# WBZ351 register map
Vendor: Microchip
Registers are 32-bit, read-write, reset 0x0 unless marked. A register's access mark holds for its fields unless they carry their own. Addresses are absolute, and some are shared; only a register's first bit layout is shown; [hi:lo] are bit positions; {n}, {i} and the like mark numbered series.

## DSU
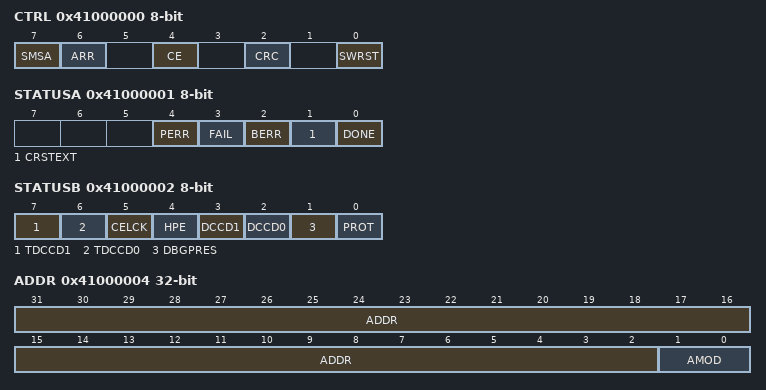
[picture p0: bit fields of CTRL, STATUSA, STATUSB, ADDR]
0x41000000 CTRL 8-bit wo
  [7] SMSA — Start Memory Stream Access
  [6] ARR — Auxiliary Row Read
  [4] CE — Chip-Erase
  [2] CRC — 32-bit Cyclic Redundancy Code
  [0] SWRST — Software Reset
0x41000001 STATUSA 8-bit
  [4] PERR — Protection Error
  [3] FAIL — Failure
  [2] BERR — Bus Error
  [1] CRSTEXT — CPU Reset Phase Extension
  [0] DONE
0x41000002 STATUSB 8-bit ro
  [7] TDCCD1 — Test Debug Communication Channel 1 Dirty
  [6] TDCCD0 — Test Debug Communication Channel 0 Dirty
  [5] CELCK — Chip Erase Locked
  [4] HPE — Hot-Plugging Enable
  [3] DCCD1 — Debug Communication Channel 1 Dirty
  [2] DCCD0 — Debug Communication Channel 0 Dirty
  [1] DBGPRES — Debugger Present
  [0] PROT — Protected
0x41000004 ADDR
  [31:2] ADDR — Address
  [1:0] AMOD — Access Mode
0x41000008 LENGTH
  [31:2] LENGTH
0x4100000C DATA
0x41000010 DCC0
  [31:0] DATA
0x41000014 DCC1
  [31:0] DATA
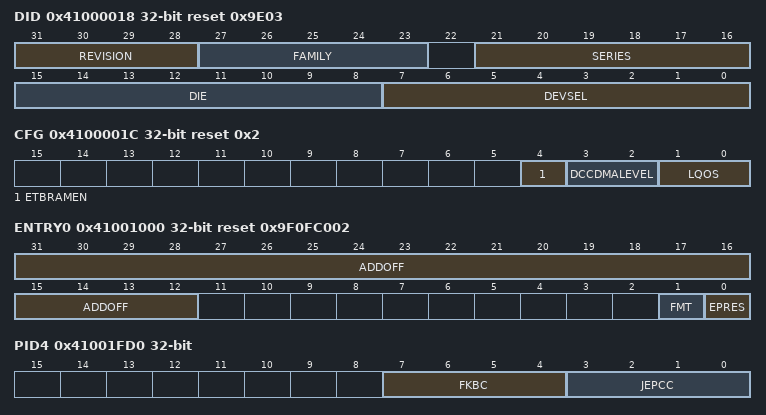
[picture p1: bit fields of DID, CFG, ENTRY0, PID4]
0x41000018 DID ro reset 0x9E03
  [31:28] REVISION — Revision Number
  [27:23] FAMILY
  [21:16] SERIES
  [15:8] DIE — Die Number
  [7:0] DEVSEL — Device Select
0x4100001C CFG reset 0x2
  [4] ETBRAMEN — Trace Control
  [3:2] DCCDMALEVEL — DMA Trigger Level
    0=EMPTY (Trigger rises when DCC is empty); 1=FULL (Trigger rises when DCC is full)
  [1:0] LQOS — Latency Quality Of Service
{0x41000038+4i} UUID{i} ro (i=0..3)
  [31:0] UUID
0x41000048 SECCFG ro
  [31:0] SECCFG — Secure Config
0x4100004C CTR_STAT ro
  [7:0] ROLLBACK_CTR — Rollback counter
0x41000050 BOOT_STAT ro
  [7:0] BOOT_STATUS
{0x41000054+4i} BOOT_KEY{i} ro (i=0..11)
  [31:0] BOOT_KEY — Secure Boot Key
0x410000F0 DCFG0
  [31:0] DCFG — Device Configuration
0x410000F4 DCFG1
  [31:0] DCFG — Device Configuration
0x41001000 ENTRY0 ro reset 0x9F0FC002
  [31:12] ADDOFF — Address Offset
  [1] FMT — Format
  [0] EPRES — Entry Present
0x41001004 ENTRY1 ro
0x41001008 END ro
  [31:0] END — End Marker
0x41001FCC MEMTYPE ro
  [0] SMEMP — System Memory Present
0x41001FD0 PID4 ro
  [7:4] FKBC — 4KB count
  [3:0] JEPCC — JEP-106 Continuation Code
0x41001FE0 PID0 ro reset 0xD0
  [7:0] PARTNBL — Part Number Low
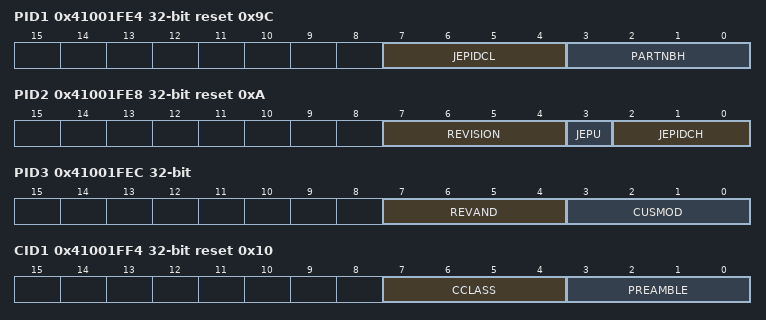
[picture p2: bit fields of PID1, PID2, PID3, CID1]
0x41001FE4 PID1 ro reset 0x9C
  [7:4] JEPIDCL — Low part of the JEP-106 Identity Code
  [3:0] PARTNBH — Part Number High
0x41001FE8 PID2 ro reset 0xA
  [7:4] REVISION — Revision Number
  [3] JEPU — JEP-106 Identity Code is used
  [2:0] JEPIDCH — JEP-106 Identity Code High
0x41001FEC PID3 ro
  [7:4] REVAND — Revision Number
  [3:0] CUSMOD — ARM CUSMOD
0x41001FF0 CID0 ro reset 0xD
  [7:0] PREAMBLEB0 — Preamble Byte 0
0x41001FF4 CID1 ro reset 0x10
  [7:4] CCLASS — Component Class
  [3:0] PREAMBLE
0x41001FF8 CID2 ro reset 0x5
  [7:0] PREAMBLEB2 — Preamble Byte 2
0x41001FFC CID3 ro reset 0xB1
  [7:0] PREAMBLEB3 — Preamble Byte 3

## CMCC
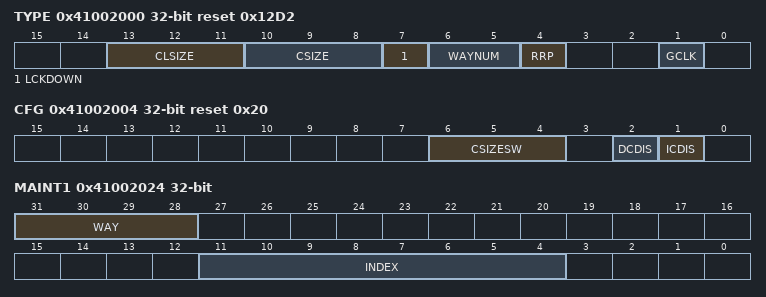
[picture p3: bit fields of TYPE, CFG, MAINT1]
0x41002000 TYPE ro reset 0x12D2
  [13:11] CLSIZE — Cache Line Size
    0=CLSIZE_4B (Cache Line Size is 4 bytes); 1=CLSIZE_8B (Cache Line Size is 8 bytes); 2=CLSIZE_16B (Cache Line Size is 16 bytes); 3=CLSIZE_32B (Cache Line Size is 32 bytes); 4=CLSIZE_64B (Cache Line Size is 64 bytes); 5=CLSIZE_128B (Cache Line Size is 128 bytes)
  [10:8] CSIZE — Cache Size
    0=CSIZE_1KB (Cache Size is 1 KB); 1=CSIZE_2KB (Cache Size is 2 KB); 2=CSIZE_4KB (Cache Size is 4 KB); 3=CSIZE_8KB (Cache Size is 8 KB); 4=CSIZE_16KB (Cache Size is 16 KB); 5=CSIZE_32KB (Cache Size is 32 KB); 6=CSIZE_64KB (Cache Size is 64 KB)
  [7] LCKDOWN — Lock Down supported
  [6:5] WAYNUM — Number of Way
    0=DMAPPED (Direct Mapped Cache); 1=ARCH2WAY (2-WAY set associative); 2=ARCH4WAY (4-WAY set associative)
  [4] RRP — Round Robin Policy supported
  [1] GCLK — dynamic Clock Gating supported
0x41002004 CFG reset 0x20
  [6:4] CSIZESW — Cache size configured by software
    0=CONF_CSIZE_1KB (The Cache Size is configured to 1KB); 1=CONF_CSIZE_2KB (The Cache Size is configured to 2KB); 2=CONF_CSIZE_4KB (The Cache Size is configured to 4KB); 3=CONF_CSIZE_8KB (The Cache Size is configured to 8KB); 4=CONF_CSIZE_16KB (The Cache Size is configured to 16KB); 5=CONF_CSIZE_32KB (The Cache Size is configured to 32KB); 6=CONF_CSIZE_64KB (The Cache Size is configured to 64KB)
  [2] DCDIS — Data Cache Disable
  [1] ICDIS — Instruction Cache Disable
0x41002008 CTRL wo
  [0] CEN — Cache Controller Enable
0x4100200C SR ro
  [0] CSTS — Cache Controller Status
0x41002010 LCKWAY
  [3:0] LCKWAY — Lockdown way Register
0x41002020 MAINT0 wo
  [0] INVALL — Cache Controller invalidate All
0x41002024 MAINT1 wo
  [31:28] WAY — Invalidate Way
    {v}=Way {v} is selection for index invalidation (v=0..3)
  [11:4] INDEX — Invalidate Index
0x41002028 MCFG
  [1:0] MODE — Cache Controller Monitor Counter Mode
    0=CYCLE_COUNT (Cycle counter); 1=IHIT_COUNT (Instruction hit counter); 2=DHIT_COUNT (Data hit counter)
0x4100202C MEN
  [0] MENABLE — Cache Controller Monitor Enable
0x41002030 MCTRL wo
  [0] SWRST — Cache Controller Software Reset
0x41002034 MSR ro
  [31:0] EVENT_CNT — Monitor Event Counter
